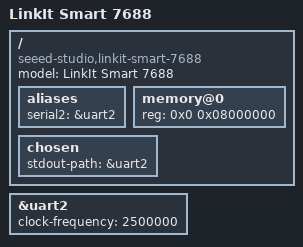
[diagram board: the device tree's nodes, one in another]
/dts-v1/;

#include "mt7688.dtsi"

/ {
	model = "LinkIt Smart 7688";
	compatible = "seeed-studio,linkit-smart-7688";

	aliases {
		serial2 = &uart2;
	};

	memory@0 {
		device_type = "memory";
		reg = <0x0 0x08000000>;
	};

	chosen {
		stdout-path = &uart2;
	};
};

&uart2 {
	status = "okay";
	clock-frequency = <2500000>;
};
